AUTOSAR XML (schema 4.0)
standard types defined: float32, float64, sint16, sint32, sint8, uint16, uint32, uint8, void, boolean
package /ImplDataTypes
  impl type BatteryLevelType: implementation-data-type=uint8, type-emitter=RTE
package /MappingSets
  data type mapping set MappingSet
package /PortInterfaces/SenderReceiver
  sender receiver interface SrIf_BatteyInfo
    data DE_BatteryLevel: type=BatteryLevelType
package /SoftwareComponents
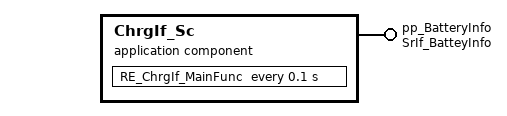
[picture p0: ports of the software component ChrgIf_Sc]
  application sw component type ChrgIf_Sc
    provide port pp_BatteryInfo: provided-interface=SrIf_BatteyInfo
    behavior Ibhv_ChrgIf_Sc: data-type-mapping=MappingSet, handle-termination-and-restart=NO-SUPPORT
      timing event TE_RE_ChrgIf_MainFunc_100ms: start-on-event=RE_ChrgIf_MainFunc, period=0.1
      runnable RE_ChrgIf_MainFunc
        data-send-points:
          access DSP_pp_BatteryInfo_DE_BatteryLevel: accessed-variable=pp_BatteryInfo.DE_BatteryLevel
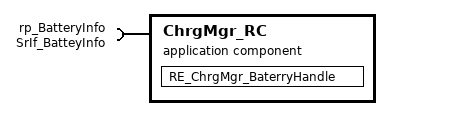
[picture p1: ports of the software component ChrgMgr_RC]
  application sw component type ChrgMgr_RC
    require port rp_BatteryInfo: required-interface=SrIf_BatteyInfo
    behavior Ibhv_ChrgMgr_RC: data-type-mapping=MappingSet, handle-termination-and-restart=NO-SUPPORT
      data received event DRE_rp_BatteryInfo_DE_BatteryLevel: start-on-event=RE_ChrgMgr_BaterryHandle, data=rp_BatteryInfo.DE_BatteryLevel
      runnable RE_ChrgMgr_BaterryHandle
        data-receive-point-by-arguments:
          access DRP_rp_BatteryInfo_DE_BatteryLevel: accessed-variable=rp_BatteryInfo.DE_BatteryLevel
  swc implementation Impl_ChrgIf_Sc: programming-language=C, sw-version=1.0.0, vendor-id=255, behavior=Ibhv_ChrgIf_Sc
    code-descriptors:
      code Code: artifact-descriptors=autosar-engineering-object={short-label=SWC.c, category=SWSRC}
    resource consumption ResourceConsumption
  swc implementation Impl_ChrgMgr_RC: programming-language=C, sw-version=1.0.0, vendor-id=255, behavior=Ibhv_ChrgMgr_RC
    code-descriptors:
      code Code: artifact-descriptors=autosar-engineering-object={short-label=SWC.c, category=SWSRC}
    resource consumption ResourceConsumption
package /Compositions
  composition sw component type BatteryLevel_SRComposition
    component ChrgIf_Sc: type=ChrgIf_Sc
    component ChrgMgr_RC: type=ChrgMgr_RC
    connect ChrgIf_Sc.pp_BatteryInfo -> ChrgMgr_RC.rp_BatteryInfo
